# STM32MP157 register map
File version: 1.6
CPU: CM4 r0p1, little endian, no MPU, FPU, 4 interrupt priority bits
Registers are 32-bit, read-write, reset 0x0 unless marked. A register's access mark holds for its fields unless they carry their own. Offsets are from the block's base; [hi:lo] are bit positions; {n}, {i} and the like mark numbered series.

## PWR
Base 0x50001000
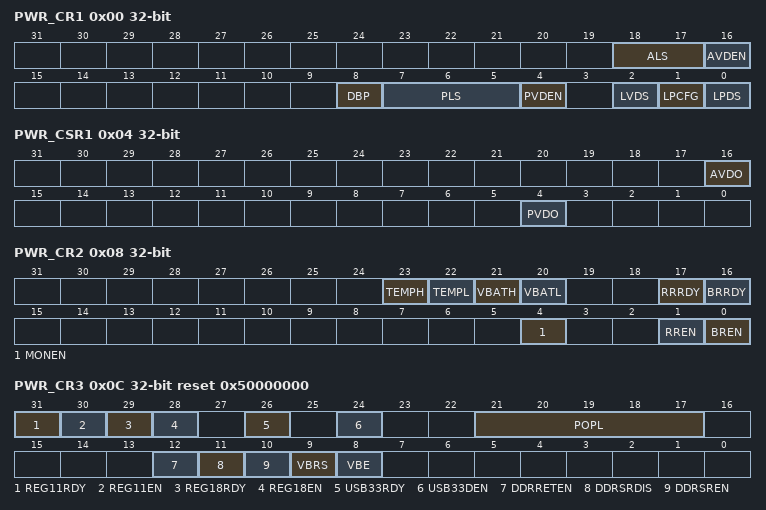
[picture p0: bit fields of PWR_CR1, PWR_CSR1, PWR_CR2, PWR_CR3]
0x00 PWR_CR1 — Reset on any system reset. This register provides write access security when enabled by TZEN register bit in Section10: Reset and clock control (RCC). When security is enabled a non-secure write access generates a bus error. Secure and non-secure read accesses are granted and return the register value.
  [18:17] ALS, [16] AVDEN, [8] DBP, [7:5] PLS, [4] PVDEN, [2] LVDS, [1] LPCFG, [0] LPDS
0x04 PWR_CSR1 ro — Reset on any system reset.
  [16] AVDO, [4] PVDO
0x08 PWR_CR2 access per field — Not reset by wakeup from Standby mode, Application reset (NRST, IWDG, ...) and VDD POR, but reset only by VSW POR and VSWRST. Access 6 wait states when writing this register. After reset the register is write-protected and the DBP bit in the PWR control register 1 (PWR_CR1) has to be set before it can be written. When DBP is cleared, there is no bus errors generated when writing this register. This register shall not be accessed when the RCC VSWRST register bit in Section10.7.89: RCC Backup Domain Control Register (RCC_BDCR) resets the VSW domain. This register provides Write access security when enabled by TZEN register bit in Section10.7.2: RCC TrustZone Control Register (RCC_TZCR). When security is enabled a non-secure write access generates a bus error. Secure and non-secure read accesses are granted and return the register value. When a system reset occurs during the register write cycle the written data is not guaranteed.
  [23] TEMPH ro, [22] TEMPL ro, [21] VBATH ro, [20] VBATL ro, [17] RRRDY ro, [16] BRRDY ro, [4] MONEN rw, [1] RREN rw, [0] BREN rw
0x0C PWR_CR3 access per field reset 0x50000000 — Not reset by wakeup from Standby mode and Application reset (such as NRST, IWDG) but only reset by VDD POR. Access 6 wait states when writing this register. This register provides Write access security when enabled by TZEN register bit in Section10: Reset and clock control (RCC). When security is enabled a non-secure write access generates a bus error. Secure and non-secure read accesses are granted and return the register value. When a system reset occurs during the register write cycle the written data is not guaranteed.
  [31] REG11RDY ro, [30] REG11EN rw, [29] REG18RDY ro, [28] REG18EN rw, [26] USB33RDY ro, [24] USB33DEN rw, [21:17] POPL rw, [12] DDRRETEN rw, [11] DDRSRDIS rw, [10] DDRSREN rw, [9] VBRS rw, [8] VBE rw
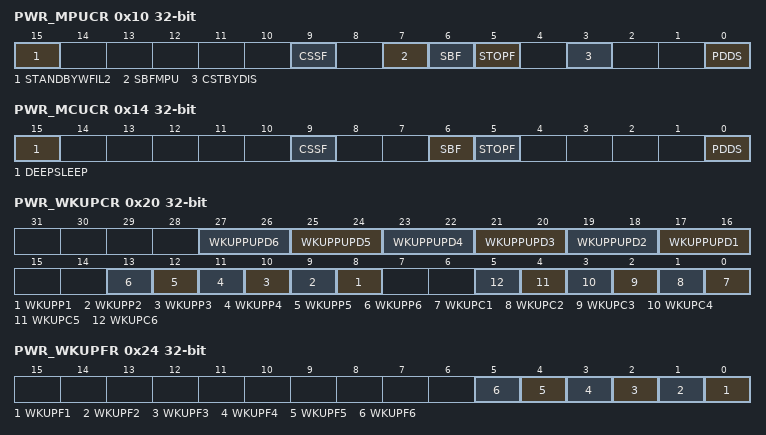
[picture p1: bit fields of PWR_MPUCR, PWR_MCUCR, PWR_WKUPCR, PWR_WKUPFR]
0x10 PWR_MPUCR access per field — See individual bits for reset condition. Access 6 wait states when writing this register. This register provides Write access security when enabled by TZEN register bit in Section10: Reset and clock control (RCC). When security is enabled a non-secure write access generates a bus error. Secure and non-secure read accesses are granted and return the register value. When a system reset occurs during the register write cycle the written data is not guaranteed.
  [15] STANDBYWFIL2 ro, [9] CSSF rw, [7] SBFMPU ro, [6] SBF ro, [5] STOPF ro, [3] CSTBYDIS rw, [0] PDDS rw
0x14 PWR_MCUCR access per field — See individual bits for reset condition. Access 6 wait states when writing this register. This register is always non-secure. When a system reset occurs during the register write cycle the written data is not guaranteed.
  [15] DEEPSLEEP ro, [9] CSSF rw, [6] SBF ro, [5] STOPF ro, [0] PDDS rw
0x20 PWR_WKUPCR — Not reset by wakeup from Standby mode, but by any application reset (such as NRST, IWDG). Access 6 wait states when writing this register (when clearing a WKUPF, the AHB write access completes after the WKUPF has cleared). This register provides Write access security when enabled by TZEN register bit in Section10: Reset and clock control (RCC). When security is enabled a non-secure write access on individual WKUPC[6:1], WKUPP[6:1] bits and WKUPPUPD[6:1] bit pairs are discarded when the corresponding WKUPEN[6:1] bit in PWR MPU wakeup enable register (PWR_MPUWKUPENR) is set. No bus error is generated. Secure and non-secure read accesses are granted and return the register value. When a system reset occurs during the register write cycle the written data is not guaranteed.
  [2n+15:2n+14] WKUPPUPD{n} (n=1..6), [n+7] WKUPP{n} (n=1..6), [n-1] WKUPC{n} (n=1..6)
0x24 PWR_WKUPFR ro — Not reset by wakeup from Standby mode but by any Application reset (NRST, IWDG, ...)
  [n-1] WKUPF{n} (n=1..6)
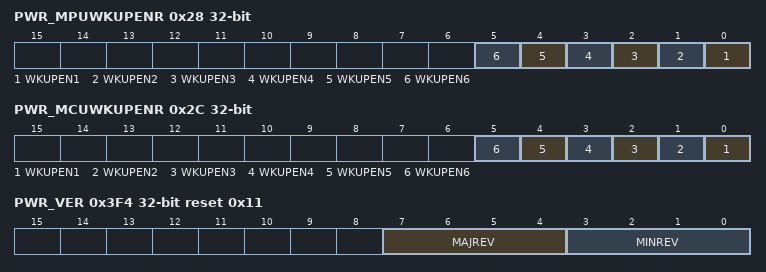
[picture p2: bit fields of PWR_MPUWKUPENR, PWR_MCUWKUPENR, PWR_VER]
0x28 PWR_MPUWKUPENR — Not reset by wakeup from Standby mode but by any Application reset (NRST, IWDG, ...). Access 6 wait states when writing this register. This register provides Write access security when enabled by TZEN register bit in Section10: Reset and clock control (RCC). When security is enabled a non-secure write access is discarded and a bus error is generated. Secure and non-secure read accesses are granted and return the register value. When a system reset occurs during the register write cycle the written data is not guaranteed.
  [n-1] WKUPEN{n} (n=1..6)
0x2C PWR_MCUWKUPENR — Not reset by wakeup from Standby mode but by any Application reset (NRST, IWDG, ...) Access 6 wait states when writing this register. When a system reset occurs during the register write cycle the written data is not guaranteed.
  [n-1] WKUPEN{n} (n=1..6)
0x3F4 PWR_VER ro reset 0x11 — PWR IP version register
  [7:4] MAJREV, [3:0] MINREV
0x3F8 PWR_ID ro reset 0x10001 — PWR IP identification register
  [31:0] IPID
0x3FC PWR_SID ro reset 0xA3C5DD01 — PWR size ID register
